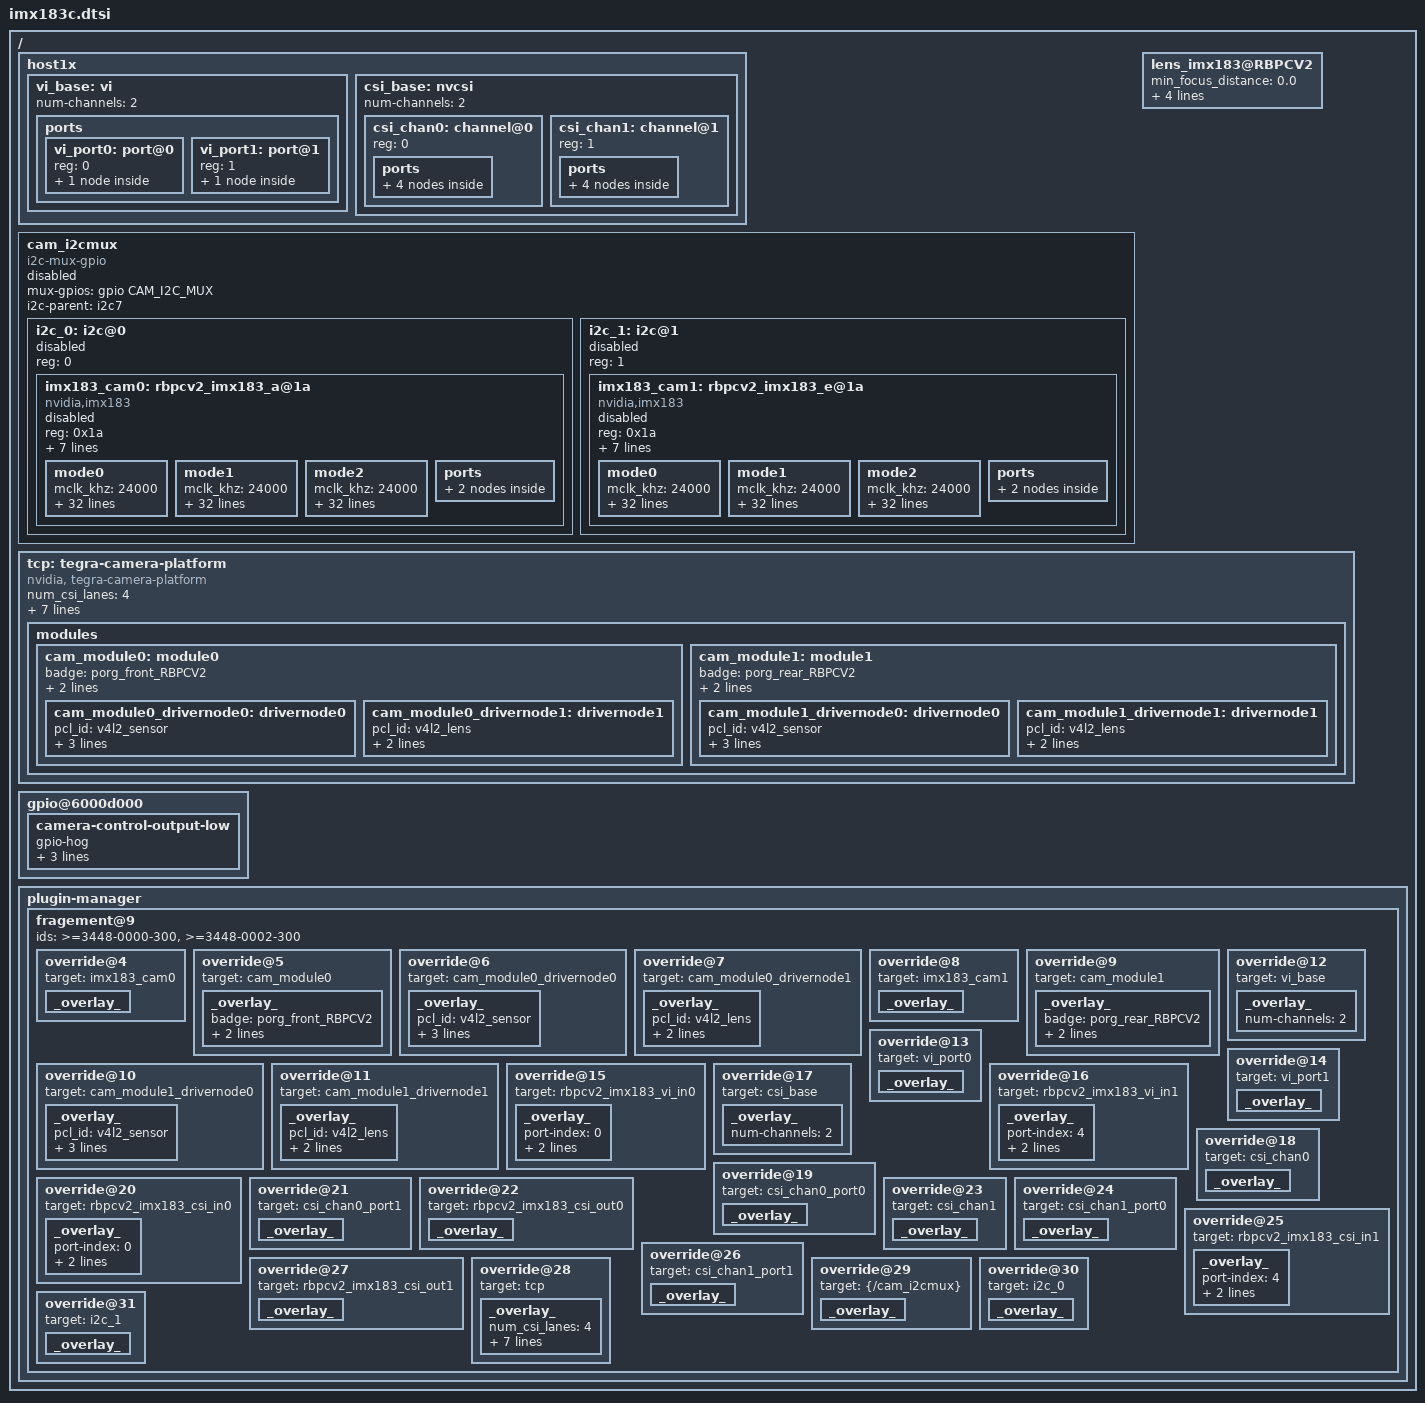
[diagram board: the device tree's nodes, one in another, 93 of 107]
/*
 * Copyright (c) 2018-2019, NVIDIA CORPORATION.  All rights reserved.
 *
 * This program is free software; you can redistribute it and/or modify
 * it under the terms of the GNU General Public License as published by
 * the Free Software Foundation; either version 2 of the License, or
 * (at your option) any later version.
 *
 * This program is distributed in the hope that it will be useful, but WITHOUT
 * ANY WARRANTY; without even the implied warranty of MERCHANTABILITY or
 * FITNESS FOR A PARTICULAR PURPOSE.  See the GNU General Public License for
 * more details.
 *
 * You should have received a copy of the GNU General Public License
 * along with this program.  If not, see <http://www.gnu.org/licenses/>.
 */

#define PIXEL_TYPE      1   /* CCC - imx183.dtsi - pixel type : 0=Y10 (gray), 1=RG10 (color) */
#define NUM_LANES       2   /* CCC - imx183.dtsi - number of lanes: 2 or 4 */
//#define EXT_TRIG_MODE  "1"  /* CCC - imx183.dtsi - external trigger mode: 0=off, 1=ext.trigger, 4=ext.trig test */

#include <dt-bindings/media/camera.h>
#include <dt-bindings/platform/t210/t210.h>

#define CAM1_PWDN       TEGRA_GPIO(S, 7)
#define CAM2_PWDN       TEGRA_GPIO(T, 0)
#define CAM_I2C_MUX TEGRA_GPIO(I, 0) // NFC_EN GPIO


/*
Jetson Nano dual-port I2C busses:
aliases {
    i2c0 = "/i2c@7000c000";
    i2c1 = "/i2c@7000c400";
    i2c2 = "/i2c@7000c500";
    i2c3 = "/i2c@7000c700";
    i2c4 = "/i2c@7000d000";
    i2c5 = "/i2c@7000d100";
    i2c6 = "/host1x/i2c@546c0000";
    i2c7 = "/cam_i2cmux/i2c@0"
    i2c8 = "/cam_i2cmux/i2c@1"

};
*/

/ {
    host1x {
        vi_base: vi {
            num-channels = <2>;
            ports {
                #address-cells = <1>;
                #size-cells = <0>;
                vi_port0: port@0 {
                    reg = <0>;
                    rbpcv2_imx183_vi_in0: endpoint {
                        port-index = <0>;
                        bus-width = <NUM_LANES>;
                        remote-endpoint = <&rbpcv2_imx183_csi_out0>;
                    };
                };
                vi_port1: port@1 {
                    reg = <1>;
                    rbpcv2_imx183_vi_in1: endpoint {
                        port-index = <4>;
                        bus-width = <NUM_LANES>;
                        remote-endpoint = <&rbpcv2_imx183_csi_out1>;
                    };
                };
            };
        };

        csi_base: nvcsi {
            num-channels = <2>;
            #address-cells = <1>;
            #size-cells = <0>;
            csi_chan0: channel@0 {
                reg = <0>;
                ports {
                    #address-cells = <1>;
                    #size-cells = <0>;
                    csi_chan0_port0: port@0 {
                        reg = <0>;
                        rbpcv2_imx183_csi_in0: endpoint@0 {
                            port-index = <0>;
                            bus-width = <NUM_LANES>;
                            remote-endpoint = <&rbpcv2_imx183_dual_out0>;
                        };
                    };
                    csi_chan0_port1: port@1 {
                        reg = <1>;
                        rbpcv2_imx183_csi_out0: endpoint@1 {
                            remote-endpoint = <&rbpcv2_imx183_vi_in0>;
                        };
                    };
                };
            };
            csi_chan1: channel@1 {
                reg = <1>;
                ports {
                    #address-cells = <1>;
                    #size-cells = <0>;
                    csi_chan1_port0: port@2 {
                        reg = <0>;
                        rbpcv2_imx183_csi_in1: endpoint@2 {
                            port-index = <4>;
                            bus-width = <NUM_LANES>;
                            remote-endpoint = <&rbpcv2_imx183_out1>;
                        };
                    };
                    csi_chan1_port1: port@3 {
                        reg = <1>;
                        rbpcv2_imx183_csi_out1: endpoint@3 {
                            remote-endpoint = <&rbpcv2_imx183_vi_in1>;
                        };
                    };
                };
            };
        };
    };

    cam_i2cmux {
        i2c_0: i2c@0 {
            imx183_cam0: rbpcv2_imx183_a@1a {
                compatible = "nvidia,imx183";
                /* I2C device address */
                reg = <0x1a>;

                /* V4L2 device node location */
                devnode = "video0";

                /* Physical dimensions of sensor */
                physical_w = "3.680";
                physical_h = "2.760";

                sensor_model = "imx183";
//#ifdef EXT_TRIG_MODE
//                external-trigger-mode = EXT_TRIG_MODE;
//#endif
                flash-output = "1";
                use_sensor_mode_id = "false";  // "false"; // "true";

                /**
                * ==== Modes ====
                * A modeX node is required to support v4l2 driver
                * implementation with NVIDIA camera software stack
                *
                * == Signal properties ==
                *
                * phy_mode = "";
                * PHY mode used by the MIPI lanes for this device
                *
                * tegra_sinterface = "";
                * CSI Serial interface connected to tegra
                * Incase of virtual HW devices, use virtual
                * For SW emulated devices, use host
                *
                * pix_clk_hz = "";
                * Sensor pixel clock used for calculations like exposure and framerate
                *
                * readout_orientation = "0";
                * Based on camera module orientation.
                * Only change readout_orientation if you specifically
                * Program a different readout order for this mode
                *
                * == Image format Properties ==
                *
                * active_w = "";
                * Pixel active region width
                *
                * active_h = "";
                * Pixel active region height
                *
                * pixel_t = "";
                * The sensor readout pixel pattern
                *
                * line_length = "";
                * Pixel line length (width) for sensor mode.
                *
                * == Source Control Settings ==
                *
                * Gain factor used to convert fixed point integer to float
                * Gain range [min_gain/gain_factor, max_gain/gain_factor]
                * Gain step [step_gain/gain_factor is the smallest step that can be configured]
                * Default gain [Default gain to be initialized for the control.
                *     use min_gain_val as default for optimal results]
                * Framerate factor used to convert fixed point integer to float
                * Framerate range [min_framerate/framerate_factor, max_framerate/framerate_factor]
                * Framerate step [step_framerate/framerate_factor is the smallest step that can be configured]
                * Default Framerate [Default framerate to be initialized for the control.
                *     use max_framerate to get required performance]
                * Exposure factor used to convert fixed point integer to float
                * For convenience use 1 sec = 1000000us as conversion factor
                * Exposure range [min_exp_time/exposure_factor, max_exp_time/exposure_factor]
                * Exposure step [step_exp_time/exposure_factor is the smallest step that can be configured]
                * Default Exposure Time [Default exposure to be initialized for the control.
                *     Set default exposure based on the default_framerate for optimal exposure settings]
                *
                * gain_factor = ""; (integer factor used for floating to fixed point conversion)
                * min_gain_val = ""; (ceil to integer)
                * max_gain_val = ""; (ceil to integer)
                * step_gain_val = ""; (ceil to integer)
                * default_gain = ""; (ceil to integer)
                * Gain limits for mode
                *
                * exposure_factor = ""; (integer factor used for floating to fixed point conversion)
                * min_exp_time = ""; (ceil to integer)
                * max_exp_time = ""; (ceil to integer)
                * step_exp_time = ""; (ceil to integer)
                * default_exp_time = ""; (ceil to integer)
                * Exposure Time limits for mode (sec)
                *
                * framerate_factor = ""; (integer factor used for floating to fixed point conversion)
                * min_framerate = ""; (ceil to integer)
                * max_framerate = ""; (ceil to integer)
                * step_framerate = ""; (ceil to integer)
                * default_framerate = ""; (ceil to integer)
                * Framerate limits for mode (fps)
                *
                * embedded_metadata_height = "";
                * Sensor embedded metadata height in units of rows.
                * If sensor does not support embedded metadata value should be 0.
                */
                mode0 { // IMX183_MODE_5440X3694 20 FPS, gray 10-bit
                    mclk_khz = "24000";
#if NUM_LANES == 4
                    num_lanes = "4";
#else
                    num_lanes = "2";
#endif
                    tegra_sinterface = "serial_a";
                    phy_mode = "DPHY";
                    discontinuous_clk = "no"; // "yes";
                    dpcm_enable = "false";
                    cil_settletime = "0";

                    active_w = "5440";
//#ifdef EXT_TRIG_MODE
//                    active_h = "3690";
//#else
                    active_h = "3692";
//#endif

#if PIXEL_TYPE == 0
                    pixel_t = "y10";            // V4L2_PIX_FMT_Y10 = 'Y10 '
#else
                    pixel_t = "bayer_rggb";     // V4L2_PIX_FMT_SRGGB10  'RG10'
#endif
//                    pixel_t = "gray";           // V4L2_PIX_FMT_GREY     'GREY'
//                    pixel_t = "bayer_rggb8";    // V4L2_PIX_FMT_SRGGB8   'RGGB'
//                    pixel_t = "bayer_rggb";     // V4L2_PIX_FMT_SRGGB10  'RG10'

                    readout_orientation = "90";
                    line_length = "6000";
                    inherent_gain = "1";
                    mclk_multiplier = "9.33";
//                    pix_clk_hz = "182400000";
//                    pix_clk_hz = "401907200";     // IMX183: 5440 * 3694 * 20 = 401907200
                    pix_clk_hz = "801907200";

                    gain_factor = "16";
                    framerate_factor = "1000000";
                    exposure_factor = "1000000";
                    min_gain_val = "0";    /* 1.00x */
                    max_gain_val = "1957"; /* 10.66x */
                    step_gain_val = "1";
                    default_gain = "0";    /* 1.00x */
                    min_hdr_ratio = "1";
                    max_hdr_ratio = "1";
                    min_framerate = "10000000"; /* 10.0 fps */
                    max_framerate = "20000000"; /* 20.0 fps */
                    step_framerate = "1";
                    default_framerate = "20000000"; /* 30.0 fps */
                    min_exp_time = "160";        /* us */
                    max_exp_time = "10000000";   /* us */
                    step_exp_time = "1";
                    default_exp_time = "10000";  /* us */

                    embedded_metadata_height = "0";   // 219: "2"
                };
                mode1 { // IMX183_MODE_5440X3694 20 FPS, gray 8-bit
                    mclk_khz = "24000";
#if NUM_LANES == 4
                    num_lanes = "4";
#else
                    num_lanes = "2";
#endif
                    tegra_sinterface = "serial_a";
                    phy_mode = "DPHY";
                    discontinuous_clk = "no"; // "yes";
                    dpcm_enable = "false";
                    cil_settletime = "0";

                    active_w = "5440";
//#ifdef EXT_TRIG_MODE
//                    active_h = "3690";
//#else
                    active_h = "3692";
//#endif

#if PIXEL_TYPE == 0
                    pixel_t = "gray";           // V4L2_PIX_FMT_GREY     'GREY'
#else
                    pixel_t = "bayer_rggb8";    // V4L2_PIX_FMT_SRGGB8   'RGGB'
#endif
//                    pixel_t = "gray";           // V4L2_PIX_FMT_GREY     'GREY'
//                    pixel_t = "y10";            // V4L2_PIX_FMT_Y10      'Y10 '
//                    pixel_t = "y12";            // V4L2_PIX_FMT_Y12      'Y12'
//                    pixel_t = "bayer_rggb8";    // V4L2_PIX_FMT_SRGGB8   'RGGB'
//                    pixel_t = "bayer_rggb";     // V4L2_PIX_FMT_SRGGB10  'RG10'
//                    pixel_t = "bayer_rggb12";   // V4L2_PIX_FMT_SRGGB12  'RG12'

                    readout_orientation = "90";
                    line_length = "6000";
                    inherent_gain = "1";
                    mclk_multiplier = "9.33";
//                    pix_clk_hz = "182400000";
//                    pix_clk_hz = "401907200";     // IMX183: 5440 * 3694 * 20 = 401907200
                    pix_clk_hz = "801907200";

                    gain_factor = "16";
                    framerate_factor = "1000000";
                    exposure_factor = "1000000";
                    min_gain_val = "0";    /* 1.00x */
                    max_gain_val = "1957"; /* 10.66x */
                    step_gain_val = "1";
                    default_gain = "0";    /* 1.00x */
                    min_hdr_ratio = "1";
                    max_hdr_ratio = "1";
                    min_framerate = "10000000"; /* 10.0 fps */
                    max_framerate = "20000000"; /* 20.0 fps */
                    step_framerate = "1";
                    default_framerate = "20000000"; /* 30.0 fps */
                    min_exp_time = "160";        /* us */
                    max_exp_time = "10000000";   /* us */
                    step_exp_time = "1";
                    default_exp_time = "10000";  /* us */

                    embedded_metadata_height = "0";   // 219: "2"
                };
                mode2 { // IMX183_MODE_5440X3694 20 FPS, bayer 12-bit
                    mclk_khz = "24000";
#if NUM_LANES == 4
                    num_lanes = "4";
#else
                    num_lanes = "2";
#endif
                    tegra_sinterface = "serial_a";
                    phy_mode = "DPHY";
                    discontinuous_clk = "no"; // "yes";
                    dpcm_enable = "false";
                    cil_settletime = "0";

                    active_w = "5440";
//#ifdef EXT_TRIG_MODE
//                    active_h = "3690";
//#else
                    active_h = "3692";
//#endif

#if PIXEL_TYPE == 0
                    pixel_t = "y12";            // V4L2_PIX_FMT_Y12      'Y12'
#else
                    pixel_t = "bayer_rggb12";   // V4L2_PIX_FMT_SRGGB12  'RG12'
#endif
//                    pixel_t = "gray";           // V4L2_PIX_FMT_GREY     'GREY'
//                    pixel_t = "y10";            // V4L2_PIX_FMT_Y10      'Y10 '
//                    pixel_t = "y12";            // V4L2_PIX_FMT_Y12      'Y12 '
//                    pixel_t = "bayer_rggb8";    // V4L2_PIX_FMT_SRGGB8   'RGGB'
//                    pixel_t = "bayer_rggb";     // V4L2_PIX_FMT_SRGGB10  'RG10'
//                    pixel_t = "bayer_rggb12";   // V4L2_PIX_FMT_SRGGB12  'RG12'

                    readout_orientation = "90";
                    line_length = "6000";
                    inherent_gain = "1";
                    mclk_multiplier = "9.33";
//                    pix_clk_hz = "182400000";
//                    pix_clk_hz = "401907200";     // IMX183: 5440 * 3694 * 20 = 401907200
                    pix_clk_hz = "801907200";

                    gain_factor = "16";
                    framerate_factor = "1000000";
                    exposure_factor = "1000000";
                    min_gain_val = "0";    /* 1.00x */
                    max_gain_val = "1957"; /* 10.66x */
                    step_gain_val = "1";
                    default_gain = "0";    /* 1.00x */
                    min_hdr_ratio = "1";
                    max_hdr_ratio = "1";
                    min_framerate = "10000000"; /* 10.0 fps */
                    max_framerate = "20000000"; /* 20.0 fps */
                    step_framerate = "1";
                    default_framerate = "20000000"; /* 30.0 fps */
                    min_exp_time = "160";        /* us */
                    max_exp_time = "10000000";   /* us */
                    step_exp_time = "1";
                    default_exp_time = "10000";  /* us */

                    embedded_metadata_height = "0";   // 219: "2"
                };

                ports {
                    #address-cells = <1>;
                    #size-cells = <0>;

                    port@0 {
                        reg = <0>;
                        rbpcv2_imx183_dual_out0: endpoint {
                            port-index = <0>;
                            bus-width = <NUM_LANES>;
                            remote-endpoint = <&rbpcv2_imx183_csi_in0>;
                        };
                    };
                };
            };
        };
        i2c_1: i2c@1 {
            imx183_cam1: rbpcv2_imx183_e@1a {
                compatible = "nvidia,imx183";
                /* I2C device address */
                reg = <0x1a>;

                /* V4L2 device node location */
                devnode = "video1";

                /* Physical dimensions of sensor */
                physical_w = "3.680";
                physical_h = "2.760";

                sensor_model = "imx183";
//#ifdef EXT_TRIG_MODE
//                external-trigger-mode = EXT_TRIG_MODE;
//#endif
                flash-output = "1";
                use_sensor_mode_id = "false";  // "false"; // "true";

                /**
                * ==== Modes ====
                * A modeX node is required to support v4l2 driver
                * implementation with NVIDIA camera software stack
                *
                * == Signal properties ==
                *
                * phy_mode = "";
                * PHY mode used by the MIPI lanes for this device
                *
                * tegra_sinterface = "";
                * CSI Serial interface connected to tegra
                * Incase of virtual HW devices, use virtual
                * For SW emulated devices, use host
                *
                * pix_clk_hz = "";
                * Sensor pixel clock used for calculations like exposure and framerate
                *
                * readout_orientation = "0";
                * Based on camera module orientation.
                * Only change readout_orientation if you specifically
                * Program a different readout order for this mode
                *
                * == Image format Properties ==
                *
                * active_w = "";
                * Pixel active region width
                *
                * active_h = "";
                * Pixel active region height
                *
                * pixel_t = "";
                * The sensor readout pixel pattern
                *
                * line_length = "";
                * Pixel line length (width) for sensor mode.
                *
                * == Source Control Settings ==
                *
                * Gain factor used to convert fixed point integer to float
                * Gain range [min_gain/gain_factor, max_gain/gain_factor]
                * Gain step [step_gain/gain_factor is the smallest step that can be configured]
                * Default gain [Default gain to be initialized for the control.
                *     use min_gain_val as default for optimal results]
                * Framerate factor used to convert fixed point integer to float
                * Framerate range [min_framerate/framerate_factor, max_framerate/framerate_factor]
                * Framerate step [step_framerate/framerate_factor is the smallest step that can be configured]
                * Default Framerate [Default framerate to be initialized for the control.
                *     use max_framerate to get required performance]
                * Exposure factor used to convert fixed point integer to float
                * For convenience use 1 sec = 1000000us as conversion factor
                * Exposure range [min_exp_time/exposure_factor, max_exp_time/exposure_factor]
                * Exposure step [step_exp_time/exposure_factor is the smallest step that can be configured]
                * Default Exposure Time [Default exposure to be initialized for the control.
                *     Set default exposure based on the default_framerate for optimal exposure settings]
                *
                * gain_factor = ""; (integer factor used for floating to fixed point conversion)
                * min_gain_val = ""; (ceil to integer)
                * max_gain_val = ""; (ceil to integer)
                * step_gain_val = ""; (ceil to integer)
                * default_gain = ""; (ceil to integer)
                * Gain limits for mode
                *
                * exposure_factor = ""; (integer factor used for floating to fixed point conversion)
                * min_exp_time = ""; (ceil to integer)
                * max_exp_time = ""; (ceil to integer)
                * step_exp_time = ""; (ceil to integer)
                * default_exp_time = ""; (ceil to integer)
                * Exposure Time limits for mode (sec)
                *
                * framerate_factor = ""; (integer factor used for floating to fixed point conversion)
                * min_framerate = ""; (ceil to integer)
                * max_framerate = ""; (ceil to integer)
                * step_framerate = ""; (ceil to integer)
                * default_framerate = ""; (ceil to integer)
                * Framerate limits for mode (fps)
                *
                * embedded_metadata_height = "";
                * Sensor embedded metadata height in units of rows.
                * If sensor does not support embedded metadata value should be 0.
                */
                mode0 { // IMX183_MODE_5440X3694 20 FPS, gray 10-bit
                    mclk_khz = "24000";
#if NUM_LANES == 4
                    num_lanes = "4";
#else
                    num_lanes = "2";
#endif
                    tegra_sinterface = "serial_e";
                    phy_mode = "DPHY";
                    discontinuous_clk = "no"; // "yes";
                    dpcm_enable = "false";
                    cil_settletime = "0";

                    active_w = "5440";
//#ifdef EXT_TRIG_MODE
//                    active_h = "3690";
//#else
                    active_h = "3692";
//#endif

#if PIXEL_TYPE == 0
                    pixel_t = "y10";            // V4L2_PIX_FMT_Y10 = 'Y10 '
#else
                    pixel_t = "bayer_rggb";     // V4L2_PIX_FMT_SRGGB10  'RG10'
#endif
//                    pixel_t = "gray";           // V4L2_PIX_FMT_GREY     'GREY'
//                    pixel_t = "bayer_rggb8";    // V4L2_PIX_FMT_SRGGB8   'RGGB'
//                    pixel_t = "bayer_rggb";     // V4L2_PIX_FMT_SRGGB10  'RG10'

                    readout_orientation = "90";
                    line_length = "6000";
                    inherent_gain = "1";
                    mclk_multiplier = "9.33";
//                    pix_clk_hz = "182400000";
//                    pix_clk_hz = "401907200";     // IMX183: 5440 * 3694 * 20 = 401907200
                    pix_clk_hz = "801907200";

                    gain_factor = "16";
                    framerate_factor = "1000000";
                    exposure_factor = "1000000";
                    min_gain_val = "0";    /* 1.00x */
                    max_gain_val = "1957"; /* 10.66x */
                    step_gain_val = "1";
                    default_gain = "0";    /* 1.00x */
                    min_hdr_ratio = "1";
                    max_hdr_ratio = "1";
                    min_framerate = "10000000"; /* 10.0 fps */
                    max_framerate = "20000000"; /* 20.0 fps */
                    step_framerate = "1";
                    default_framerate = "20000000"; /* 30.0 fps */
                    min_exp_time = "160";        /* us */
                    max_exp_time = "10000000";   /* us */
                    step_exp_time = "1";
                    default_exp_time = "10000";  /* us */

                    embedded_metadata_height = "0";   // 219: "2"
                };
                mode1 { // IMX183_MODE_5440X3694 20 FPS, gray 8-bit
                    mclk_khz = "24000";
#if NUM_LANES == 4
                    num_lanes = "4";
#else
                    num_lanes = "2";
#endif
                    tegra_sinterface = "serial_a";
                    phy_mode = "DPHY";
                    discontinuous_clk = "no"; // "yes";
                    dpcm_enable = "false";
                    cil_settletime = "0";

                    active_w = "5440";
//#ifdef EXT_TRIG_MODE
//                    active_h = "3690";
//#else
                    active_h = "3692";
//#endif

#if PIXEL_TYPE == 0
                    pixel_t = "gray";           // V4L2_PIX_FMT_GREY     'GREY'
#else
                    pixel_t = "bayer_rggb8";    // V4L2_PIX_FMT_SRGGB8   'RGGB'
#endif
//                    pixel_t = "gray";           // V4L2_PIX_FMT_GREY     'GREY'
//                    pixel_t = "y10";            // V4L2_PIX_FMT_Y10      'Y10 '
//                    pixel_t = "y12";            // V4L2_PIX_FMT_Y12      'Y12 '
//                    pixel_t = "bayer_rggb8";    // V4L2_PIX_FMT_SRGGB8   'RGGB'
//                    pixel_t = "bayer_rggb";     // V4L2_PIX_FMT_SRGGB10  'RG10'
//                    pixel_t = "bayer_rggb12";   // V4L2_PIX_FMT_SRGGB12  'RG12'

                    readout_orientation = "90";
                    line_length = "6000";
                    inherent_gain = "1";
                    mclk_multiplier = "9.33";
//                    pix_clk_hz = "182400000";
//                    pix_clk_hz = "401907200";     // IMX183: 5440 * 3694 * 20 = 401907200
                    pix_clk_hz = "801907200";

                    gain_factor = "16";
                    framerate_factor = "1000000";
                    exposure_factor = "1000000";
                    min_gain_val = "0";    /* 1.00x */
                    max_gain_val = "1957"; /* 10.66x */
                    step_gain_val = "1";
                    default_gain = "0";    /* 1.00x */
                    min_hdr_ratio = "1";
                    max_hdr_ratio = "1";
                    min_framerate = "10000000"; /* 10.0 fps */
                    max_framerate = "20000000"; /* 20.0 fps */
                    step_framerate = "1";
                    default_framerate = "20000000"; /* 30.0 fps */
                    min_exp_time = "160";        /* us */
                    max_exp_time = "10000000";   /* us */
                    step_exp_time = "1";
                    default_exp_time = "10000";  /* us */

                    embedded_metadata_height = "0";   // 219: "2"
                };
                mode2 { // IMX183_MODE_5440X3694 20 FPS, bayer 12-bit
                    mclk_khz = "24000";
#if NUM_LANES == 4
                    num_lanes = "4";
#else
                    num_lanes = "2";
#endif
                    tegra_sinterface = "serial_a";
                    phy_mode = "DPHY";
                    discontinuous_clk = "no"; // "yes";
                    dpcm_enable = "false";
                    cil_settletime = "0";

                    active_w = "5440";
//#ifdef EXT_TRIG_MODE
//                    active_h = "3690";
//#else
                    active_h = "3692";
//#endif

#if PIXEL_TYPE == 0
                    pixel_t = "y12";            // V4L2_PIX_FMT_Y12      'Y12'
#else
                    pixel_t = "bayer_rggb12";   // V4L2_PIX_FMT_SRGGB12  'RG12'
#endif
//                    pixel_t = "gray";           // V4L2_PIX_FMT_GREY     'GREY'
//                    pixel_t = "y10";            // V4L2_PIX_FMT_Y10      'Y10 '
//                    pixel_t = "y12";            // V4L2_PIX_FMT_Y12      'Y12 '
//                    pixel_t = "bayer_rggb8";    // V4L2_PIX_FMT_SRGGB8   'RGGB'
//                    pixel_t = "bayer_rggb";     // V4L2_PIX_FMT_SRGGB10  'RG10'
//                    pixel_t = "bayer_rggb12";   // V4L2_PIX_FMT_SRGGB12  'RG12'

                    readout_orientation = "90";
                    line_length = "6000";
                    inherent_gain = "1";
                    mclk_multiplier = "9.33";
//                    pix_clk_hz = "182400000";
//                    pix_clk_hz = "401907200";     // IMX183: 5440 * 3694 * 20 = 401907200
                    pix_clk_hz = "801907200";

                    gain_factor = "16";
                    framerate_factor = "1000000";
                    exposure_factor = "1000000";
                    min_gain_val = "0";    /* 1.00x */
                    max_gain_val = "1957"; /* 10.66x */
                    step_gain_val = "1";
                    default_gain = "0";    /* 1.00x */
                    min_hdr_ratio = "1";
                    max_hdr_ratio = "1";
                    min_framerate = "10000000"; /* 10.0 fps */
                    max_framerate = "20000000"; /* 20.0 fps */
                    step_framerate = "1";
                    default_framerate = "20000000"; /* 30.0 fps */
                    min_exp_time = "160";        /* us */
                    max_exp_time = "10000000";   /* us */
                    step_exp_time = "1";
                    default_exp_time = "10000";  /* us */

                    embedded_metadata_height = "0";   // 219: "2"
                };

                ports {
                    #address-cells = <1>;
                    #size-cells = <0>;

                    port@0 {
                        reg = <0>;
                        rbpcv2_imx183_out1: endpoint {
                            port-index = <4>;
                            bus-width = <NUM_LANES>;
                            remote-endpoint = <&rbpcv2_imx183_csi_in1>;
                        };
                    };
                };
            };
        };
    };

    lens_imx183@RBPCV2 {
        min_focus_distance = "0.0";
        hyper_focal = "0.0";
        focal_length = "3.04";
        f_number = "2.0";
        aperture = "0.0";
    };
};

/ {
    tcp: tegra-camera-platform {
        compatible = "nvidia, tegra-camera-platform";

        /**
        * Physical settings to calculate max ISO BW
        *
        * num_csi_lanes = <>;
        * Total number of CSI lanes when all cameras are active
        *
        * max_lane_speed = <>;
        * Max lane speed in Kbit/s
        *
        * min_bits_per_pixel = <>;
        * Min bits per pixel
        *
        * vi_peak_byte_per_pixel = <>;
        * Max byte per pixel for the VI ISO case
        *
        * vi_bw_margin_pct = <>;
        * Vi bandwidth margin in percentage
        *
        * max_pixel_rate = <>;
        * Max pixel rate in Kpixel/s for the ISP ISO case
        *
        * isp_peak_byte_per_pixel = <>;
        * Max byte per pixel for the ISP ISO case
        *
        * isp_bw_margin_pct = <>;
        * Isp bandwidth margin in percentage
        */
        num_csi_lanes = <4>;
        max_lane_speed = <1500000>;
        min_bits_per_pixel = <10>;
        vi_peak_byte_per_pixel = <2>;
        vi_bw_margin_pct = <25>;
        max_pixel_rate = <240000>;
        isp_peak_byte_per_pixel = <5>;
        isp_bw_margin_pct = <25>;

        /**
         * The general guideline for naming badge_info contains 3 parts, and is as follows,
         * The first part is the camera_board_id for the module; if the module is in a FFD
         * platform, then use the platform name for this part.
         * The second part contains the position of the module, ex. "rear" or "front".
         * The third part contains the last 6 characters of a part number which is found
         * in the module's specsheet from the vendor.
         */
        modules {
            cam_module0: module0 {
                badge = "porg_front_RBPCV2";
                position = "front";
                orientation = "1";
                cam_module0_drivernode0: drivernode0 {
                    pcl_id = "v4l2_sensor";
                    devname = "imx183 7-001a";
                    proc-device-tree = "/proc/device-tree/cam_i2cmux/i2c@0/rbpcv2_imx183_a@1a";
                };
                cam_module0_drivernode1: drivernode1 {
                    pcl_id = "v4l2_lens";
                    proc-device-tree = "/proc/device-tree/lens_imx183@RBPCV2/";
                };
            };
            cam_module1: module1 {
                badge = "porg_rear_RBPCV2";
                position = "rear";
                orientation = "1";
                cam_module1_drivernode0: drivernode0 {
                    pcl_id = "v4l2_sensor";
                    devname = "imx183 8-001a";
                    proc-device-tree = "/proc/device-tree/cam_i2cmux/i2c@1/rbpcv2_imx183_e@1a";
                };
                cam_module1_drivernode1: drivernode1 {
                    pcl_id = "v4l2_lens";
                    proc-device-tree = "/proc/device-tree/lens_imx183@RBPCV2/";
                };
            };
        };
    };
};


/ {
    cam_i2cmux {
        compatible = "i2c-mux-gpio";
        #address-cells = <1>;
        #size-cells = <0>;
        mux-gpios = <&gpio CAM_I2C_MUX GPIO_ACTIVE_HIGH>;
        i2c-parent = <&i2c7>;
        status = "disabled";
        i2c@0 {
            status = "disabled";
            reg = <0>;
            #address-cells = <1>;
            #size-cells = <0>;
            rbpcv2_imx183_a@1a {
                status = "disabled";
                reset-gpios = <&gpio CAM1_PWDN GPIO_ACTIVE_HIGH>;
            };
        };
        i2c@1 {
            status = "disabled";
            reg = <1>;
            #address-cells = <1>;
            #size-cells = <0>;
            rbpcv2_imx183_e@1a {
                status = "disabled";
                reset-gpios = <&gpio CAM2_PWDN GPIO_ACTIVE_HIGH>;
            };
        };
    };

    gpio@6000d000 {
        camera-control-output-low {
            gpio-hog;
            output-low;
            gpios = < CAM1_PWDN 0  CAM2_PWDN 0>;
            label = "cam1-pwdn", "cam2-pwdn";
        };
    };
};

/ {
    plugin-manager {
// Fragment VC_MIPI IMX327C dual sensor
        fragement@9 {
            ids = ">=3448-0000-300", ">=3448-0002-300";

//            override@0 {
//                target = <&{/pcie@1003000/pci@2,0}>;
//                _overlay_ {
//                    nvidia,plat-gpios = <&gpio TEGRA_GPIO(CC, 7) GPIO_ACTIVE_HIGH>;
//                };
//            };
//            override@1 {
//                target = <&sdhci2>;
//                _overlay_ {
//                    vqmmc-supply = <&max77620_ldo6>;
//                    no-sdio;
//                    no-mmc;
//                    sd-uhs-sdr104;
//                    sd-uhs-sdr50;
//                    sd-uhs-sdr25;
//                    sd-uhs-sdr12;
//                };
//            };
//            override@2 {
//                target = <&throttle_oc1>;
//                _overlay_ {
//                    nvidia,priority = <50>;
//                    nvidia,polarity-active-low = <1>;
//                    nvidia,count-threshold = <1>;
//                    nvidia,alarm-filter = <5100000>;
//                    nvidia,alarm-period = <0>;
//                    nvidia,cpu-throt-percent = <75>;
//                    nvidia,gpu-throt-level =
//                        <TEGRA_SOCTHERM_THROT_LEVEL_HIGH>;
//                };
//            };
//            override@3 {
//                target = <&{/leds}>;
//                _overlay_ {
//                    status = "okay";
//                };
//            };

            /* IMX183 dual sensor module */
            override@4 {
                target = <&imx183_cam0>;
                _overlay_ {
                    status = "okay";
                };
            };
            override@5 {
                target = <&cam_module0>;
                _overlay_ {
                    status = "okay";
                    badge = "porg_front_RBPCV2";
                    position = "front";
                    orientation = "1";
                };
            };
            override@6 {
                target = <&cam_module0_drivernode0>;
                _overlay_ {
                    status = "okay";
                    pcl_id = "v4l2_sensor";
                    devname = "imx183 7-001a";
                    proc-device-tree = "/proc/device-tree/cam_i2cmux/i2c@0/rbpcv2_imx183_a@1a";
                };
            };
            override@7 {
                target = <&cam_module0_drivernode1>;
                _overlay_ {
                    status = "okay";
                    pcl_id = "v4l2_lens";
                    proc-device-tree = "/proc/device-tree/lens_imx183@RBPCV2/";
                };
            };
            override@8 {
                target = <&imx183_cam1>;
                _overlay_ {
                    status = "okay";
                };
            };
            override@9 {
                target = <&cam_module1>;
                _overlay_ {
                    status = "okay";
                    badge = "porg_rear_RBPCV2";
                    position = "rear";
                    orientation = "1";
                };
            };
            override@10 {
                target = <&cam_module1_drivernode0>;
                _overlay_ {
                    status = "okay";
                    pcl_id = "v4l2_sensor";
                    devname = "imx183 8-001a";
                    proc-device-tree = "/proc/device-tree/cam_i2cmux/i2c@1/rbpcv2_imx183_e@1a";
                };
            };
            override@11 {
                target = <&cam_module1_drivernode1>;
                _overlay_ {
                    status = "okay";
                    pcl_id = "v4l2_lens";
                    proc-device-tree = "/proc/device-tree/lens_imx183@RBPCV2/";
                };
            };
            /* Enable VI ports */
            override@12 {
                target = <&vi_base>;
                _overlay_ {
                    num-channels=<2>;
                };
            };
            override@13 {
                target = <&vi_port0>;
                _overlay_ {
                    status = "okay";
                };
            };
            override@14 {
                target = <&vi_port1>;
                _overlay_ {
                    status = "okay";
                };
            };
            override@15 {
                target = <&rbpcv2_imx183_vi_in0>;
                _overlay_ {
                    status = "okay";
                    port-index = <0>;
                    bus-width = <NUM_LANES>;
                    remote-endpoint = <&rbpcv2_imx183_csi_out0>;
                };
            };
            override@16 {
                target = <&rbpcv2_imx183_vi_in1>;
                _overlay_ {
                    status = "okay";
                    port-index = <4>;
                    bus-width = <NUM_LANES>;
                    remote-endpoint = <&rbpcv2_imx183_csi_out1>;
                };
            };
            /* Enable CSI ports */
            override@17 {
                target = <&csi_base>;
                _overlay_ {
                    num-channels = <2>;
                };
            };
            override@18 {
                target = <&csi_chan0>;
                _overlay_ {
                    status = "okay";
                };
            };
            override@19 {
                target = <&csi_chan0_port0>;
                _overlay_ {
                    status = "okay";
                };
            };
            override@20 {
                target = <&rbpcv2_imx183_csi_in0>;
                _overlay_ {
                    status = "okay";
                    port-index = <0>;
                    bus-width = <NUM_LANES>;
                    remote-endpoint = <&rbpcv2_imx183_dual_out0>;
                };
            };
            override@21 {
                target = <&csi_chan0_port1>;
                _overlay_ {
                    status = "okay";
                };
            };
            override@22 {
                target = <&rbpcv2_imx183_csi_out0>;
                _overlay_ {
                    status = "okay";
                };
            };
            override@23 {
                target = <&csi_chan1>;
                _overlay_ {
                    status = "okay";
                };
            };
            override@24 {
                target = <&csi_chan1_port0>;
                _overlay_ {
                    status = "okay";
                };
            };
            override@25 {
                target = <&rbpcv2_imx183_csi_in1>;
                _overlay_ {
                    status = "okay";
                    port-index = <4>;
                    bus-width = <NUM_LANES>;
                    remote-endpoint = <&rbpcv2_imx183_out1>;
                };
            };
            override@26 {
                target = <&csi_chan1_port1>;
                _overlay_ {
                    status = "okay";
                };
            };
            override@27 {
                target = <&rbpcv2_imx183_csi_out1>;
                _overlay_ {
                    status = "okay";
                };
            };
            /* tegra-camera-platform settings */
            override@28 {
                target = <&tcp>;
                _overlay_ {
                    num_csi_lanes = <4>;
                    max_lane_speed = <1500000>;
                    min_bits_per_pixel = <10>;
                    vi_peak_byte_per_pixel = <2>;
                    vi_bw_margin_pct = <25>;
                    max_pixel_rate = <240000>;
                    isp_peak_byte_per_pixel = <5>;
                    isp_bw_margin_pct = <25>;
                };
            };
            /* gpio based i2c mux */
            override@29 {
                target = <&{/cam_i2cmux}>;
                _overlay_ {
                    status = "okay";
                };
            };
            override@30 {
                target = <&i2c_0>;
                _overlay_ {
                    status = "okay";
                };
            };
            override@31 {
                target = <&i2c_1>;
                _overlay_ {
                    status = "okay";
                };
            };
        };

    };
};
